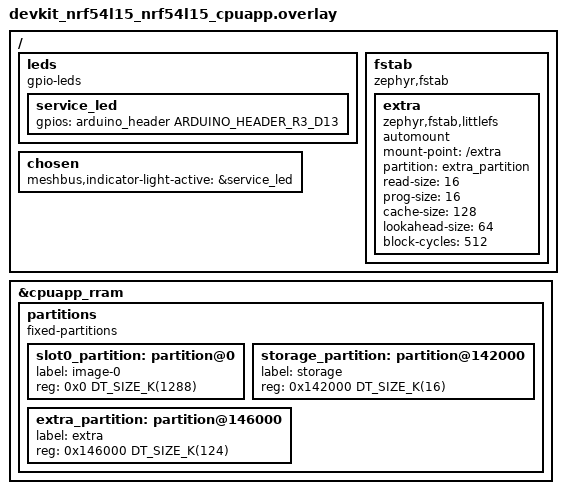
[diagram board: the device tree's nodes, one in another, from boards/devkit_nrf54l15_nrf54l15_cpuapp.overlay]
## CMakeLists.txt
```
# SPDX-License-Identifier: Apache-2.0

cmake_minimum_required(VERSION 3.20.0)

find_package(Zephyr REQUIRED HINTS $ENV{ZEPHYR_BASE})
project(llext_service)

FILE(GLOB app_sources src/*.c)
target_sources(app PRIVATE ${app_sources})
```

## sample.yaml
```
sample:
  name: Meshbus LLEXT service
  description: Starts Meshbus LLEXT boot service manager for board shell and upload validation
common:
  tags:
    - meshbus
    - llext
  harness: console
  harness_config:
    type: one_line
    regex:
      - "Meshbus LLEXT boot service sample started"
tests:
  sample.subsys.meshbus.services.llext:
    platform_allow:
      - devkit_nrf54l15/nrf54l15/cpuapp
      - idea_mesh_tracker_c2/nrf54l15/cpuapp
    integration_platforms:
      - devkit_nrf54l15/nrf54l15/cpuapp
      - idea_mesh_tracker_c2/nrf54l15/cpuapp
```

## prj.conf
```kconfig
# Logging
CONFIG_LOG=y
CONFIG_LOG_MODE_IMMEDIATE=y

# Kernel
CONFIG_MAIN_STACK_SIZE=4096
CONFIG_SYSTEM_WORKQUEUE_STACK_SIZE=4096
CONFIG_HEAP_MEM_POOL_SIZE=98304
CONFIG_DYNAMIC_THREAD=y
CONFIG_DYNAMIC_THREAD_ALLOC=y

# Shell Management
CONFIG_SHELL=y
CONFIG_SHELL_CMD_BUFF_SIZE=512
CONFIG_SHELL_STACK_SIZE=16384
CONFIG_SHELL_BACKEND_SERIAL=y
CONFIG_SHELL_BACKEND_DUMMY=y

# File system
CONFIG_FILE_SYSTEM=y
CONFIG_FILE_SYSTEM_SHELL=y
CONFIG_FILE_SYSTEM_LITTLEFS=y
CONFIG_FS_LITTLEFS_FC_HEAP_SIZE=2048
CONFIG_FLASH=y
CONFIG_FLASH_MAP=y
CONFIG_FLASH_PAGE_LAYOUT=y

# Meshbus + llext boot service manager
CONFIG_MESHBUS=y
CONFIG_MESHBUS_SHELL=y
CONFIG_ZBUS_RUNTIME_OBSERVERS=y
CONFIG_MESHBUS_INDICATOR=y
CONFIG_MESHBUS_INDICATOR_SHELL=y
CONFIG_MESHBUS_LLEXT=y
CONFIG_MESHBUS_LLEXT_SHELL=y
CONFIG_MESHBUS_LLEXT_LOG_LEVEL=4
CONFIG_MESHBUS_LLEXT_BOOT_SERVICES=y
CONFIG_MESHBUS_LLEXT_MAX_SERVICES=4
CONFIG_MESHBUS_LLEXT_DEFAULT_PATH="/extra/svcs"

# Zephyr llext core
CONFIG_LLEXT=y
CONFIG_LLEXT_HEAP_DYNAMIC=y
CONFIG_MESHBUS_LLEXT_DYNAMIC_HEAP_MARGIN_PERCENT=5

# Utils
CONFIG_NET_BUF=y
CONFIG_ZCBOR=y
CONFIG_CRC=y
CONFIG_BASE64=y

# MCUmgr Management
CONFIG_MCUMGR=y
CONFIG_MCUMGR_TRANSPORT_NETBUF_SIZE=2475
CONFIG_MCUMGR_TRANSPORT_WORKQUEUE_STACK_SIZE=4608
CONFIG_MCUMGR_TRANSPORT_SHELL=y
CONFIG_MCUMGR_GRP_ENUM=y
CONFIG_MCUMGR_GRP_ENUM_DETAILS=y
CONFIG_MCUMGR_GRP_ENUM_DETAILS_NAME=y
CONFIG_MCUMGR_GRP_OS=y
CONFIG_MCUMGR_GRP_OS_ECHO=y
CONFIG_MCUMGR_GRP_OS_INFO=y
CONFIG_MCUMGR_GRP_OS_TASKSTAT=y
CONFIG_MCUMGR_GRP_OS_BOOTLOADER_INFO=y
CONFIG_MCUMGR_GRP_OS_MCUMGR_PARAMS=y
CONFIG_MCUMGR_GRP_FS=y
CONFIG_MCUMGR_GRP_FS_FILE_STATUS=y
CONFIG_MCUMGR_GRP_FS_FILE_ACCESS_HOOK=y
CONFIG_MCUMGR_GRP_FS_CHECKSUM_HASH=y
CONFIG_MCUMGR_GRP_FS_CHECKSUM_HASH_SUPPORTED_CMD=y
CONFIG_MCUMGR_GRP_FS_CHECKSUM_IEEE_CRC32=y
CONFIG_MCUMGR_GRP_FS_HASH_SHA256=y
CONFIG_MCUMGR_GRP_ZBASIC=y
CONFIG_MCUMGR_GRP_ZBASIC_STORAGE_ERASE=y
CONFIG_MCUMGR_GRP_STAT=y
CONFIG_MCUMGR_GRP_STAT_MAX_NAME_LEN=32
CONFIG_MCUMGR_GRP_SETTINGS=y
CONFIG_MCUMGR_GRP_SETTINGS_ACCESS_HOOK=y
CONFIG_MCUMGR_GRP_SETTINGS_VALUE_LEN=128
CONFIG_MCUMGR_GRP_SHELL=y
CONFIG_MCUMGR_MGMT_NOTIFICATION_HOOKS=y

CONFIG_ZMS=y
CONFIG_ZMS_LOOKUP_CACHE=y
CONFIG_ZMS_LOOKUP_CACHE_SIZE=512
CONFIG_ZMS_LOOKUP_CACHE_FOR_SETTINGS=y
CONFIG_SETTINGS=y
CONFIG_SETTINGS_ZMS=y
CONFIG_SETTINGS_ZMS_LL_CACHE=y
CONFIG_SETTINGS_ZMS_LL_CACHE_SIZE=512
CONFIG_SETTINGS_SHELL=y
CONFIG_SETTINGS_RUNTIME=y
CONFIG_SETTINGS_DYNAMIC_HANDLERS=y
```

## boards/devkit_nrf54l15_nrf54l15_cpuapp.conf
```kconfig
# SPDX-License-Identifier: Apache-2.0

CONFIG_USERSPACE=n
CONFIG_MPU=n
CONFIG_ARM_MPU=n

CONFIG_SERIAL=y
CONFIG_UART_INTERRUPT_DRIVEN=y

CONFIG_GPIO=y
CONFIG_LED=y
CONFIG_PWM=n
```

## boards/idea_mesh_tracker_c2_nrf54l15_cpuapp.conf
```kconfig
# SPDX-License-Identifier: Apache-2.0

CONFIG_USERSPACE=n
CONFIG_MPU=n
CONFIG_ARM_MPU=n

# Keep serial and flash/fs support explicit for shell + littlefs workflow
CONFIG_SERIAL=y
CONFIG_UART_INTERRUPT_DRIVEN=y

# Indicator service peripheral dependencies
CONFIG_GPIO=y
CONFIG_PWM=y
CONFIG_LED=y

# Power domain support used by board indicator chosen nodes
CONFIG_PM_DEVICE=y
CONFIG_PM_DEVICE_RUNTIME=y
CONFIG_PM_DEVICE_SHELL=y
CONFIG_POWER_DOMAIN=y
CONFIG_PM_DEVICE_POWER_DOMAIN=y
CONFIG_PM_DEVICE_RUNTIME_ASYNC=y
```

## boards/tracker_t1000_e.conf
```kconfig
# Nordic SoC
CONFIG_SOC_FLASH_NRF_EMULATE_ONE_BYTE_WRITE_ACCESS=y
CONFIG_USERSPACE=n
CONFIG_MPU=n
CONFIG_ARM_MPU=n

# Peripherals
CONFIG_GPIO=y
CONFIG_GPIO_HOGS=y
CONFIG_PWM=y
CONFIG_LED=y
CONFIG_LED_PWM=n
CONFIG_SERIAL=y
CONFIG_UART_INTERRUPT_DRIVEN=y

# Indicator service peripheral dependencies
CONFIG_PM_DEVICE=y
CONFIG_PM_DEVICE_RUNTIME=y
CONFIG_PM_DEVICE_SHELL=y
CONFIG_POWER_DOMAIN=y
CONFIG_PM_DEVICE_POWER_DOMAIN=y
CONFIG_PM_DEVICE_RUNTIME_ASYNC=y

# Bluetooth
CONFIG_BT=y
CONFIG_BT_PERIPHERAL=y
CONFIG_BT_DEVICE_NAME="MeshCore-FoBE"
CONFIG_BT_RX_STACK_SIZE=2048
CONFIG_BT_APP_PASSKEY=y
CONFIG_BT_BONDABLE=y
CONFIG_BT_SETTINGS=y
CONFIG_BT_MAX_CONN=1
CONFIG_BT_MAX_PAIRED=5
CONFIG_BT_DIS=y
CONFIG_BT_DIS_MANUF_NAME=y
CONFIG_BT_DIS_MANUF_NAME_STR="Seeed"
CONFIG_BT_DIS_MODEL_NUMBER=y
CONFIG_BT_DIS_MODEL_NUMBER_STR="T1000-E"
CONFIG_BT_BAS=y
CONFIG_BT_TPS=y

# The OS datetime group is unavailable in this Zephyr revision.
CONFIG_MCUMGR_GRP_OS_DATETIME=n
CONFIG_MCUMGR_GRP_OS_DATETIME_HOOK=n
```

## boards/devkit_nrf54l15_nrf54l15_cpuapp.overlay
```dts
/* SPDX-License-Identifier: Apache-2.0 */

/ {
	leds {
		compatible = "gpio-leds";
		service_led: service_led {
			gpios = <&arduino_header ARDUINO_HEADER_R3_D13 GPIO_ACTIVE_HIGH>;
		};
	};

	fstab: fstab {
		compatible = "zephyr,fstab";
		extra: extra {
			compatible = "zephyr,fstab,littlefs";
			automount;
			mount-point = "/extra";
			partition = <&extra_partition>;
			read-size = <16>;
			prog-size = <16>;
			cache-size = <128>;
			lookahead-size = <64>;
			block-cycles = <512>;
		};
	};

	chosen {
		meshbus,indicator-light-active = &service_led;
	};
};

&cpuapp_rram {
	/delete-node/ partitions;

	partitions {
		compatible = "fixed-partitions";
		#address-cells = <1>;
		#size-cells = <1>;
		ranges;

		slot0_partition: partition@0 {
			label = "image-0";
			reg = <0x0 DT_SIZE_K(1288)>;
		};

		storage_partition: partition@142000 {
			label = "storage";
			reg = <0x142000 DT_SIZE_K(16)>;
		};

		extra_partition: partition@146000 {
			label = "extra";
			reg = <0x146000 DT_SIZE_K(124)>;
		};
	};
};
```

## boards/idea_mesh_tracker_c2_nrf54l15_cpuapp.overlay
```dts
/*
 * Copyright (c) 2026 FoBE Studio
 *
 * SPDX-License-Identifier: Apache-2.0
 */

/ {
	fstab: fstab {
		compatible = "zephyr,fstab";
		extra: extra {
			compatible = "zephyr,fstab,littlefs";
			automount;
			mount-point = "/extra";
			partition = <&extra_partition>;
			read-size = <16>;
			prog-size = <16>;
			cache-size = <128>;
			lookahead-size = <64>;
			block-cycles = <512>;
		};
	};

	chosen {
		meshbus,indicator-light-active = &led0;
		meshbus,indicator-buzzer = &pwm20;
		meshbus,indicator-buzzer-power = &peripheral_power;
		meshbus,indicator-light-power = &peripheral_power;
	};
};

&cpuapp_rram {
	/delete-node/ partitions;

	partitions {
		compatible = "fixed-partitions";
		#address-cells = <1>;
		#size-cells = <1>;
		ranges;

		boot_partition: partition@0 {
			label = "mcuboot";
			reg = <0x0 DT_SIZE_K(64)>;
		};

		slot0_partition: partition@10000 {
			label = "image-0";
			reg = <0x10000 DT_SIZE_K(612)>;
		};

		slot1_partition: partition@a9000 {
			label = "image-1";
			reg = <0xa9000 DT_SIZE_K(612)>;
		};

		storage_partition: partition@142000 {
			label = "storage";
			reg = <0x142000 DT_SIZE_K(16)>;
		};

		extra_partition: partition@146000 {
			label = "extra";
			reg = <0x146000 DT_SIZE_K(124)>;
		};
	};
};
```

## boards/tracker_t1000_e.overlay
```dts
/*
 * SPDX-License-Identifier: Apache-2.0
 */

/ {
	fstab: fstab {
		compatible = "zephyr,fstab";
		extra: extra {
			compatible = "zephyr,fstab,littlefs";
			automount;
			mount-point = "/extra";
			partition = <&lfs_partition>;
			read-size = <16>;
			prog-size = <16>;
			cache-size = <128>;
			lookahead-size = <64>;
			block-cycles = <512>;
		};
	};

	chosen {
		meshbus,indicator-light-active = &led0;
		meshbus,indicator-buzzer = &pwm0;
		meshbus,indicator-buzzer-power = &buzzer_power;
	};
};
```

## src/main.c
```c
/*
 * Copyright (c) 2026 FoBE Studio
 *
 * SPDX-License-Identifier: Apache-2.0
 */

#include <zephyr/drivers/gpio.h>
#include <zephyr/kernel.h>
#include <zephyr/logging/log.h>

LOG_MODULE_REGISTER(meshbus_llext_sample, LOG_LEVEL_INF);

int main(void)
{
	LOG_INF("Meshbus LLEXT boot service sample started");
	LOG_INF("Install service artifacts as /extra/svcs/*.mbs");
	LOG_INF("New services run after the next device reboot");
	LOG_INF("Use: meshbus llext service list|status <id>");

	return 0;
}
```
